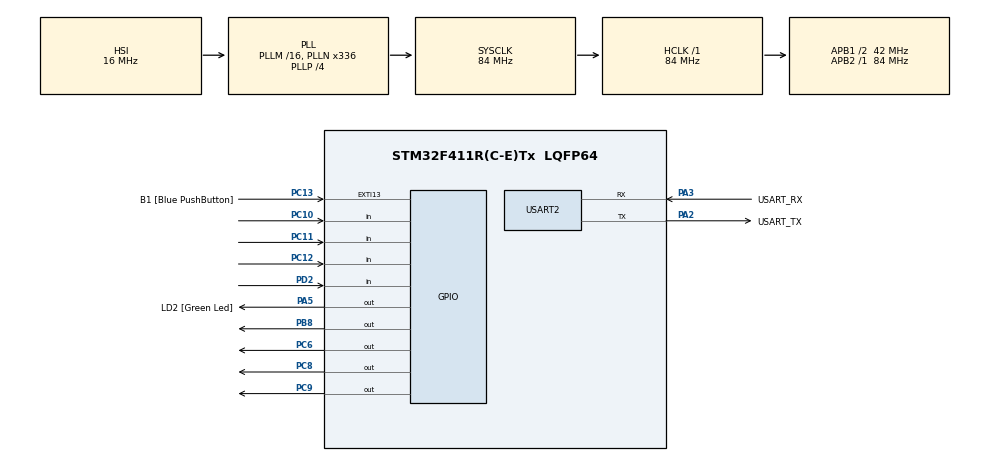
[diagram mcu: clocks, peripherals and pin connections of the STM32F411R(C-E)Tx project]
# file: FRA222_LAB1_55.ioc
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Mcu.Family=STM32F4
Mcu.Name=STM32F411R(C-E)Tx
Mcu.Package=LQFP64
NVIC.PriorityGroup=NVIC_PRIORITYGROUP_0
PA13.GPIO_Label=TMS
PA13.Mode=Serial_Wire
PA13.Signal=SYS_JTMS-SWDIO
PA14.GPIO_Label=TCK
PA14.Mode=Serial_Wire
PA14.Signal=SYS_JTCK-SWCLK
PA2.GPIO_Label=USART_TX
PA2.Mode=Asynchronous
PA2.Signal=USART2_TX
PA3.GPIO_Label=USART_RX
PA3.Mode=Asynchronous
PA3.Signal=USART2_RX
PA5.GPIO_Label=LD2 [Green Led]
PA5.Signal=GPIO_Output
PB3.GPIO_Label=SWO
PB3.Signal=SYS_JTDO-SWO
PB8.Signal=GPIO_Output
PC10.GPIO_PuPd=GPIO_PULLUP
PC10.Signal=GPIO_Input
PC11.GPIO_PuPd=GPIO_PULLUP
PC11.Signal=GPIO_Input
PC12.GPIO_PuPd=GPIO_PULLUP
PC12.Signal=GPIO_Input
PC13-ANTI_TAMP.GPIO_Label=B1 [Blue PushButton]
PC13-ANTI_TAMP.GPIO_ModeDefaultEXTI=GPIO_MODE_IT_FALLING
PC13-ANTI_TAMP.Signal=GPXTI13
PC14-OSC32_IN.Mode=LSE-External-Oscillator
PC14-OSC32_IN.Signal=RCC_OSC32_IN
PC15-OSC32_OUT.Mode=LSE-External-Oscillator
PC15-OSC32_OUT.Signal=RCC_OSC32_OUT
PC6.Signal=GPIO_Output
PC8.Signal=GPIO_Output
PC9.Signal=GPIO_Output
PD2.GPIO_PuPd=GPIO_PULLUP
PD2.Signal=GPIO_Input
PH0\ -\ OSC_IN.Mode=HSE-External-Clock-Source
PH0\ -\ OSC_IN.Signal=RCC_OSC_IN
PH1\ -\ OSC_OUT.Mode=HSE-External-Clock-Source
PH1\ -\ OSC_OUT.Signal=RCC_OSC_OUT
ProjectManager.HeapSize=0x200
ProjectManager.StackSize=0x400
ProjectManager.TargetToolchain=STM32CubeIDE
RCC.48MHZClocksFreq_Value=84000000
RCC.AHBFreq_Value=84000000
RCC.APB1CLKDivider=RCC_HCLK_DIV2
RCC.APB1Freq_Value=42000000
RCC.APB1TimFreq_Value=84000000
RCC.APB2Freq_Value=84000000
RCC.APB2TimFreq_Value=84000000
RCC.CortexFreq_Value=84000000
RCC.FLatency-AdvancedSettings=FLASH_LATENCY_2
RCC.HCLKFreq_Value=84000000
RCC.HSE_VALUE=8000000
RCC.HSI_VALUE=16000000
RCC.PLLN=336
RCC.PLLP=RCC_PLLP_DIV4
RCC.SYSCLKFreq_VALUE=84000000
RCC.SYSCLKSource=RCC_SYSCLKSOURCE_PLLCLK
RCC.VCOOutputFreq_Value=336000000
USART2.VirtualMode=VM_ASYNC
board=NUCLEO-F411RE

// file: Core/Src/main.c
/* USER CODE BEGIN Header */
/**
 ******************************************************************************
 * @file           : main.c
 * @brief          : Main program body
 ******************************************************************************
 * @attention
 *
 * Copyright (c) 2023 STMicroelectronics.
 * All rights reserved.
 *
 * This software is licensed under terms that can be found in the LICENSE file
 * in the root directory of this software component.
 * If no LICENSE file comes with this software, it is provided AS-IS.
 *
 ******************************************************************************
 */
/* USER CODE END Header */
#include "main.h"

/* USER CODE BEGIN Includes */
 //Alungran Petjit
/* USER CODE END Includes */

UART_HandleTypeDef huart2;

/* USER CODE BEGIN PV */

//L1 = PC10
//L2 = PC11
//L3 = PC12
//L4 = PD2

//R1 = PC9
//R2 = PC8
//R3 = PB8
//R4 = PC6

// create matrix to store variable in matrix 4*4 = 16
static int keep_button[16];
static int assign_button[16];
static int column = 0;

static int current_button;
static int last_button;

//input the button value into matrix
void assign(){
	for(int var = 0; var < 16; var++){
		assign_button[var] = keep_button[var];
	}
}

//check the row if any got pressed
void get_val(int row) {

	current_button = 0;
	//define which row we are at
	keep_button[row * 4] = HAL_GPIO_ReadPin(GPIOC, GPIO_PIN_10);
	keep_button[row * 4 + 1] = HAL_GPIO_ReadPin(GPIOC, GPIO_PIN_11);
	keep_button[row * 4 + 2] = HAL_GPIO_ReadPin(GPIOC, GPIO_PIN_12);
	keep_button[row * 4 + 3] = HAL_GPIO_ReadPin(GPIOD, GPIO_PIN_2);

	//check if botton is pressed
	for(int var = 0; var < row * 4 + 4;var++){
		if(keep_button[var] == 0){
			current_button = 1;
			break;
		}
	}

}

//When that button is pressed return the value
int see_val() {
	for (int var = 0; var < 16; ++var) {
		if (assign_button[var] == 0) {
			return var+1;
		}
	}
}

void password(){
	static int number_state = 0;

	switch (number_state) {
		case 0:
			HAL_GPIO_WritePin(GPIOA, GPIO_PIN_5, GPIO_PIN_RESET);

			if (see_val() == 10) {
				number_state += 1; //6
			}
			else if (see_val() == 13) {
				number_state = 0;
			}
			else if (see_val() != 10){
				number_state = 13;
			}
			break;
		case 1:

			if (see_val() == 2) {
				number_state += 1; //64
			}
			else if (see_val() == 13) {
				number_state = 0;
			}
			else if (see_val() != 2){
				number_state = 13;
			}
			break;
		case 2:

			if (see_val() == 11) {
				number_state += 1; //643
			}
			else if (see_val() == 13) {
				number_state = 0;
			}
			else if (see_val() != 11){
				number_state = 13;
			}
			break;
		case 3:

			if (see_val() == 2) {
				number_state += 1; //6434
			}
			else if (see_val() == 13) {
				number_state = 0;
			}
			else if (see_val() != 2){
				number_state = 13;
			}
			break;
		case 4:

			if (see_val() == 4) {
				number_state += 1; //64340
			}
			else if (see_val() == 13) {
				number_state = 0;
			}
			else if (see_val() != 4){
				number_state = 13;
			}
			break;
		case 5:

			if (see_val() == 6) {
				number_state += 1; //643405
			}
			else if (see_val() == 13) {
				number_state = 0;
			}
			else if (see_val() != 6){
				number_state = 13;
			}
			break;
		case 6:

			if (see_val() == 4) {
				number_state += 1; //6434050
			}
			else if (see_val() == 13) {
				number_state = 0;
			}
			else if (see_val() != 4){
				number_state = 13;
			}
			break;
		case 7:

			if (see_val() == 4) {
				number_state += 1; //64340500
			}
			else if (see_val() == 13) {
				number_state = 0;
			}
			else if (see_val() != 4){
				number_state = 13;
			}
			break;
		case 8:

			if (see_val() == 4) {
				number_state += 1; //643405000
			}
			else if (see_val() == 13) {
				number_state = 0;
			}
			else if (see_val() != 4){
				number_state = 13;
			}
			break;
		case 9:

			if (see_val() == 6) {
				number_state += 1; //6434050005
			}
			else if (see_val() == 13) {
				number_state = 0;
			}
			else if (see_val() != 6){
				number_state = 13;
			}
			break;
		case 10:

			if (see_val() == 6) {
				number_state += 1; //64340500055
			}
			else if (see_val() == 13) {
				number_state = 0;
			}
			else if (see_val() != 6){
				number_state = 13;
			}
			break;
		case 11:

			if (see_val() == 16) {
				HAL_GPIO_WritePin(GPIOA, GPIO_PIN_5, GPIO_PIN_SET);
				number_state = 12 ; //OK
			}
			else if (see_val() == 13) {
				number_state = 0;
			}
			else if (see_val() != 16){
				number_state = 13;
			}

			break;
		case 12:
			if (see_val() == 13){
				HAL_GPIO_WritePin(GPIOA, GPIO_PIN_5, GPIO_PIN_RESET);
				number_state = 0;
			}

		break;
		case 13:
			if (see_val() == 13)
			{
				number_state = 0;
			}

		break;

		}
}

/* USER CODE END PV */

void SystemClock_Config(void);
static void MX_GPIO_Init(void);
static void MX_USART2_UART_Init(void);

int main(void)
{

  /* MCU Configuration--------------------------------------------------------*/

  /* Reset of all peripherals, Initializes the Flash interface and the Systick. */
  HAL_Init();

  /* Configure the system clock */
  SystemClock_Config();

  /* Initialize all configured peripherals */
  MX_GPIO_Init();
  MX_USART2_UART_Init();
  /* USER CODE BEGIN 2 */
  static uint32_t timestamp1 = 10;
  GPIO_PinState HIGH = 1;
  GPIO_PinState LOW = 0;
  /* USER CODE END 2 */

  /* Infinite loop */
	while (1)
	{

    /* USER CODE BEGIN 3 */

		if (timestamp1 <= HAL_GetTick()){
			timestamp1 = HAL_GetTick() + 10;

			switch(column) {
			case 0:

					HAL_GPIO_WritePin(GPIOC, GPIO_PIN_9, LOW);
					get_val(column);
					HAL_GPIO_WritePin(GPIOC, GPIO_PIN_9, HIGH);
					HAL_GPIO_WritePin(GPIOC, GPIO_PIN_8, LOW);
					column++;

			break;
			case 1:
					get_val(column);
					HAL_GPIO_WritePin(GPIOC, GPIO_PIN_8, HIGH);
					HAL_GPIO_WritePin(GPIOB, GPIO_PIN_8, LOW);
					column++;
			break;

			case 2:

					get_val(column);
					HAL_GPIO_WritePin(GPIOB, GPIO_PIN_8, HIGH);
					HAL_GPIO_WritePin(GPIOC, GPIO_PIN_6, LOW);
					column++;
			break;

			case 3:

					get_val(column);
					HAL_GPIO_WritePin(GPIOC, GPIO_PIN_6, HIGH);
					HAL_GPIO_WritePin(GPIOC, GPIO_PIN_9, LOW);

					if(current_button == 1)
					{
						assign();
					}
					if (last_button == 1 && current_button == 0)
					{
						password();
					}

				last_button = current_button;
				column = 0;
				break;

			}

		}

	}
  /* USER CODE END 3 */
}

void SystemClock_Config(void)
{
  RCC_OscInitTypeDef RCC_OscInitStruct = {0};
  RCC_ClkInitTypeDef RCC_ClkInitStruct = {0};

  /** Configure the main internal regulator output voltage
  */
  __HAL_RCC_PWR_CLK_ENABLE();
  __HAL_PWR_VOLTAGESCALING_CONFIG(PWR_REGULATOR_VOLTAGE_SCALE1);

  /** Initializes the RCC Oscillators according to the specified parameters
  * in the RCC_OscInitTypeDef structure.
  */
  RCC_OscInitStruct.OscillatorType = RCC_OSCILLATORTYPE_HSI;
  RCC_OscInitStruct.HSIState = RCC_HSI_ON;
  RCC_OscInitStruct.HSICalibrationValue = RCC_HSICALIBRATION_DEFAULT;
  RCC_OscInitStruct.PLL.PLLState = RCC_PLL_ON;
  RCC_OscInitStruct.PLL.PLLSource = RCC_PLLSOURCE_HSI;
  RCC_OscInitStruct.PLL.PLLM = 16;
  RCC_OscInitStruct.PLL.PLLN = 336;
  RCC_OscInitStruct.PLL.PLLP = RCC_PLLP_DIV4;
  RCC_OscInitStruct.PLL.PLLQ = 4;
  if (HAL_RCC_OscConfig(&RCC_OscInitStruct) != HAL_OK)
  {
    Error_Handler();
  }

  /** Initializes the CPU, AHB and APB buses clocks
  */
  RCC_ClkInitStruct.ClockType = RCC_CLOCKTYPE_HCLK|RCC_CLOCKTYPE_SYSCLK
                              |RCC_CLOCKTYPE_PCLK1|RCC_CLOCKTYPE_PCLK2;
  RCC_ClkInitStruct.SYSCLKSource = RCC_SYSCLKSOURCE_PLLCLK;
  RCC_ClkInitStruct.AHBCLKDivider = RCC_SYSCLK_DIV1;
  RCC_ClkInitStruct.APB1CLKDivider = RCC_HCLK_DIV2;
  RCC_ClkInitStruct.APB2CLKDivider = RCC_HCLK_DIV1;

  if (HAL_RCC_ClockConfig(&RCC_ClkInitStruct, FLASH_LATENCY_2) != HAL_OK)
  {
    Error_Handler();
  }
}

static void MX_USART2_UART_Init(void)
{

  huart2.Instance = USART2;
  huart2.Init.BaudRate = 115200;
  huart2.Init.WordLength = UART_WORDLENGTH_8B;
  huart2.Init.StopBits = UART_STOPBITS_1;
  huart2.Init.Parity = UART_PARITY_NONE;
  huart2.Init.Mode = UART_MODE_TX_RX;
  huart2.Init.HwFlowCtl = UART_HWCONTROL_NONE;
  huart2.Init.OverSampling = UART_OVERSAMPLING_16;
  if (HAL_UART_Init(&huart2) != HAL_OK)
  {
    Error_Handler();
  }

}

static void MX_GPIO_Init(void)
{
  GPIO_InitTypeDef GPIO_InitStruct = {0};

  /* GPIO Ports Clock Enable */
  __HAL_RCC_GPIOC_CLK_ENABLE();
  __HAL_RCC_GPIOH_CLK_ENABLE();
  __HAL_RCC_GPIOA_CLK_ENABLE();
  __HAL_RCC_GPIOD_CLK_ENABLE();
  __HAL_RCC_GPIOB_CLK_ENABLE();

  /*Configure GPIO pin Output Level */
  HAL_GPIO_WritePin(GPIOA, GPIO_PIN_0|LD2_Pin, GPIO_PIN_RESET);

  /*Configure GPIO pin Output Level */
  HAL_GPIO_WritePin(GPIOC, GPIO_PIN_6|GPIO_PIN_8|GPIO_PIN_9, GPIO_PIN_RESET);

  /*Configure GPIO pin Output Level */
  HAL_GPIO_WritePin(GPIOB, GPIO_PIN_8, GPIO_PIN_RESET);

  /*Configure GPIO pin : B1_Pin */
  GPIO_InitStruct.Pin = B1_Pin;
  GPIO_InitStruct.Mode = GPIO_MODE_IT_FALLING;
  GPIO_InitStruct.Pull = GPIO_NOPULL;
  HAL_GPIO_Init(B1_GPIO_Port, &GPIO_InitStruct);

  /*Configure GPIO pins : PA0 LD2_Pin */
  GPIO_InitStruct.Pin = GPIO_PIN_0|LD2_Pin;
  GPIO_InitStruct.Mode = GPIO_MODE_OUTPUT_PP;
  GPIO_InitStruct.Pull = GPIO_NOPULL;
  GPIO_InitStruct.Speed = GPIO_SPEED_FREQ_LOW;
  HAL_GPIO_Init(GPIOA, &GPIO_InitStruct);

  /*Configure GPIO pins : PC6 PC8 PC9 */
  GPIO_InitStruct.Pin = GPIO_PIN_6|GPIO_PIN_8|GPIO_PIN_9;
  GPIO_InitStruct.Mode = GPIO_MODE_OUTPUT_PP;
  GPIO_InitStruct.Pull = GPIO_NOPULL;
  GPIO_InitStruct.Speed = GPIO_SPEED_FREQ_LOW;
  HAL_GPIO_Init(GPIOC, &GPIO_InitStruct);

  /*Configure GPIO pins : PC10 PC11 PC12 */
  GPIO_InitStruct.Pin = GPIO_PIN_10|GPIO_PIN_11|GPIO_PIN_12;
  GPIO_InitStruct.Mode = GPIO_MODE_INPUT;
  GPIO_InitStruct.Pull = GPIO_PULLUP;
  HAL_GPIO_Init(GPIOC, &GPIO_InitStruct);

  /*Configure GPIO pin : PD2 */
  GPIO_InitStruct.Pin = GPIO_PIN_2;
  GPIO_InitStruct.Mode = GPIO_MODE_INPUT;
  GPIO_InitStruct.Pull = GPIO_PULLUP;
  HAL_GPIO_Init(GPIOD, &GPIO_InitStruct);

  /*Configure GPIO pin : PB8 */
  GPIO_InitStruct.Pin = GPIO_PIN_8;
  GPIO_InitStruct.Mode = GPIO_MODE_OUTPUT_PP;
  GPIO_InitStruct.Pull = GPIO_NOPULL;
  GPIO_InitStruct.Speed = GPIO_SPEED_FREQ_LOW;
  HAL_GPIO_Init(GPIOB, &GPIO_InitStruct);

}

void Error_Handler(void)
{
				__disable_irq();
				while (1) {
				}
}
